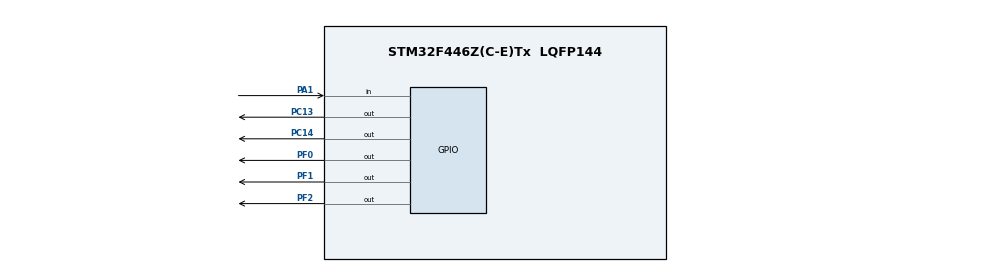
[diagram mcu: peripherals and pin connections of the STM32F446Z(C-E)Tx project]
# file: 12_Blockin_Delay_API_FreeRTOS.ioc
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FREERTOS.Tasks01=defaultTask,26,128,StartDefaultTask,Default,NULL,Dynamic,NULL,NULL;myTask02,27,128,StartTask02,Default,NULL,Dynamic,NULL,NULL
Mcu.Family=STM32F4
Mcu.Name=STM32F446Z(C-E)Tx
Mcu.Package=LQFP144
NVIC.PriorityGroup=NVIC_PRIORITYGROUP_4
PA1.Signal=GPIO_Input
PA2.Signal=USART2_TX
PA3.Signal=USART2_RX
PC13.Signal=GPIO_Output
PC14-OSC32_IN.Signal=GPIO_Output
PF0.Signal=GPIO_Output
PF1.Signal=GPIO_Output
PF2.Signal=GPIO_Output
ProjectManager.HeapSize=0x200
ProjectManager.StackSize=0x400
ProjectManager.TargetToolchain=STM32CubeIDE
RCC.CortexFreq_Value=16000000
RCC.USBFreq_Value=96000000
RCC.VCOOutputFreq_Value=192000000
VP_FREERTOS_VS_CMSIS_V2.Mode=CMSIS_V2
board=custom

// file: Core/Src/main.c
/* USER CODE BEGIN Header */
/**
  ******************************************************************************
  * @file           : main.c
  * @brief          : Main program body
  ******************************************************************************
  * @attention
  *
  * Copyright (c) 2024 STMicroelectronics.
  * All rights reserved.
  *
  * This software is licensed under terms that can be found in the LICENSE file
  * in the root directory of this software component.
  * If no LICENSE file comes with this software, it is provided AS-IS.
  *
  ******************************************************************************
  */
/* USER CODE END Header */
#include "main.h"
#include "cmsis_os.h"

/* USER CODE BEGIN Includes */
#include "string.h"
#include "stdio.h"
/* USER CODE END Includes */

/* Definitions for defaultTask */
osThreadId_t defaultTaskHandle;
const osThreadAttr_t defaultTask_attributes = {
  .name = "defaultTask",
  .stack_size = 128 * 4,
  .priority = (osPriority_t) osPriorityNormal2,
};
/* Definitions for myTask02 */
osThreadId_t myTask02Handle;
const osThreadAttr_t myTask02_attributes = {
  .name = "myTask02",
  .stack_size = 128 * 4,
  .priority = (osPriority_t) osPriorityNormal3,
};

void SystemClock_Config(void);
static void MX_GPIO_Init(void);
void StartDefaultTask(void *argument);
void StartTask02(void *argument);

/* USER CODE BEGIN 0 */
char myMessage[100];
/* USER CODE END 0 */

int main(void)
{

  /* MCU Configuration--------------------------------------------------------*/

  /* Reset of all peripherals, Initializes the Flash interface and the Systick. */
  HAL_Init();

  /* Configure the system clock */
  SystemClock_Config();

  /* Initialize all configured peripherals */
  MX_GPIO_Init();

  /* Init scheduler */
  osKernelInitialize();

  /* Create the thread(s) */
  /* creation of defaultTask */
  defaultTaskHandle = osThreadNew(StartDefaultTask, NULL, &defaultTask_attributes);

  /* creation of myTask02 */
  myTask02Handle = osThreadNew(StartTask02, NULL, &myTask02_attributes);

  /* Start scheduler */
  osKernelStart();

  /* We should never get here as control is now taken by the scheduler */
  /* Infinite loop */
  while (1)
  {

  }
}

void SystemClock_Config(void)
{
  RCC_OscInitTypeDef RCC_OscInitStruct = {0};
  RCC_ClkInitTypeDef RCC_ClkInitStruct = {0};

  /** Configure the main internal regulator output voltage
  */
  __HAL_RCC_PWR_CLK_ENABLE();
  __HAL_PWR_VOLTAGESCALING_CONFIG(PWR_REGULATOR_VOLTAGE_SCALE3);

  /** Initializes the RCC Oscillators according to the specified parameters
  * in the RCC_OscInitTypeDef structure.
  */
  RCC_OscInitStruct.OscillatorType = RCC_OSCILLATORTYPE_HSI;
  RCC_OscInitStruct.HSIState = RCC_HSI_ON;
  RCC_OscInitStruct.HSICalibrationValue = RCC_HSICALIBRATION_DEFAULT;
  RCC_OscInitStruct.PLL.PLLState = RCC_PLL_NONE;
  if (HAL_RCC_OscConfig(&RCC_OscInitStruct) != HAL_OK)
  {
    Error_Handler();
  }

  /** Initializes the CPU, AHB and APB buses clocks
  */
  RCC_ClkInitStruct.ClockType = RCC_CLOCKTYPE_HCLK|RCC_CLOCKTYPE_SYSCLK
                              |RCC_CLOCKTYPE_PCLK1|RCC_CLOCKTYPE_PCLK2;
  RCC_ClkInitStruct.SYSCLKSource = RCC_SYSCLKSOURCE_HSI;
  RCC_ClkInitStruct.AHBCLKDivider = RCC_SYSCLK_DIV1;
  RCC_ClkInitStruct.APB1CLKDivider = RCC_HCLK_DIV1;
  RCC_ClkInitStruct.APB2CLKDivider = RCC_HCLK_DIV1;

  if (HAL_RCC_ClockConfig(&RCC_ClkInitStruct, FLASH_LATENCY_0) != HAL_OK)
  {
    Error_Handler();
  }
}

static void MX_GPIO_Init(void)
{
  GPIO_InitTypeDef GPIO_InitStruct = {0};

  /* GPIO Ports Clock Enable */
  __HAL_RCC_GPIOC_CLK_ENABLE();
  __HAL_RCC_GPIOF_CLK_ENABLE();
  __HAL_RCC_GPIOA_CLK_ENABLE();

  /*Configure GPIO pin Output Level */
  HAL_GPIO_WritePin(GPIOC, GPIO_PIN_13|GPIO_PIN_14, GPIO_PIN_RESET);

  /*Configure GPIO pin Output Level */
  HAL_GPIO_WritePin(GPIOF, GPIO_PIN_0|GPIO_PIN_1|GPIO_PIN_2, GPIO_PIN_RESET);

  /*Configure GPIO pins : PC13 PC14 */
  GPIO_InitStruct.Pin = GPIO_PIN_13|GPIO_PIN_14;
  GPIO_InitStruct.Mode = GPIO_MODE_OUTPUT_PP;
  GPIO_InitStruct.Pull = GPIO_NOPULL;
  GPIO_InitStruct.Speed = GPIO_SPEED_FREQ_LOW;
  HAL_GPIO_Init(GPIOC, &GPIO_InitStruct);

  /*Configure GPIO pins : PF0 PF1 PF2 */
  GPIO_InitStruct.Pin = GPIO_PIN_0|GPIO_PIN_1|GPIO_PIN_2;
  GPIO_InitStruct.Mode = GPIO_MODE_OUTPUT_PP;
  GPIO_InitStruct.Pull = GPIO_NOPULL;
  GPIO_InitStruct.Speed = GPIO_SPEED_FREQ_LOW;
  HAL_GPIO_Init(GPIOF, &GPIO_InitStruct);

  /*Configure GPIO pin : PA1 */
  GPIO_InitStruct.Pin = GPIO_PIN_1;
  GPIO_InitStruct.Mode = GPIO_MODE_INPUT;
  GPIO_InitStruct.Pull = GPIO_NOPULL;
  HAL_GPIO_Init(GPIOA, &GPIO_InitStruct);

  /*Configure GPIO pins : PA2 PA3 */
  GPIO_InitStruct.Pin = GPIO_PIN_2|GPIO_PIN_3;
  GPIO_InitStruct.Mode = GPIO_MODE_AF_PP;
  GPIO_InitStruct.Pull = GPIO_NOPULL;
  GPIO_InitStruct.Speed = GPIO_SPEED_FREQ_VERY_HIGH;
  GPIO_InitStruct.Alternate = GPIO_AF7_USART2;
  HAL_GPIO_Init(GPIOA, &GPIO_InitStruct);

}

void StartDefaultTask(void *argument)
{
  /* USER CODE BEGIN 5 */
  /* Infinite loop */
  for(;;)
  {
    sprintf(myMessage," Status of the leds: %d\r\n", HAL_GPIO_ReadPin(GPIOF, GPIO_PIN_0 | GPIO_PIN_1 | GPIO_PIN_2));
    vTaskDelay(pdMS_TO_TICKS(1000));
  }
  /* USER CODE END 5 */
}

void StartTask02(void *argument)
{
  /* USER CODE BEGIN StartTask02 */
  /* Infinite loop */
  for(;;)
  {
	  HAL_GPIO_TogglePin(GPIOF, GPIO_PIN_0 | GPIO_PIN_1 | GPIO_PIN_2);
      vTaskDelay(pdMS_TO_TICKS(100));
  }
  /* USER CODE END StartTask02 */
}

void Error_Handler(void)
{
  __disable_irq();
  while (1)
  {
  }
}
